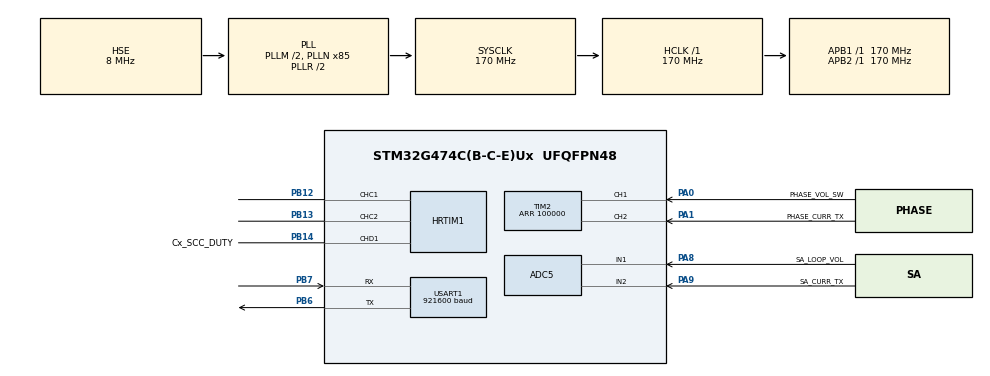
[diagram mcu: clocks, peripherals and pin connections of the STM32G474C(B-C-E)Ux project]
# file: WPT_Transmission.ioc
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ADC5.Channel-0\#ChannelRegularConversion=ADC_CHANNEL_1
ADC5.Channel-1\#ChannelRegularConversion=ADC_CHANNEL_2
ADC5.ClockPrescaler=ADC_CLOCK_SYNC_PCLK_DIV4
ADC5.ContinuousConvMode=ENABLE
ADC5.DMAContinuousRequests=ENABLE
ADC5.NbrOfConversion=2
ADC5.NbrOfConversionFlag=1
ADC5.OffsetNumber-0\#ChannelRegularConversion=ADC_OFFSET_NONE
ADC5.OffsetNumber-1\#ChannelRegularConversion=ADC_OFFSET_NONE
ADC5.Overrun=ADC_OVR_DATA_OVERWRITTEN
ADC5.Rank-0\#ChannelRegularConversion=1
ADC5.Rank-1\#ChannelRegularConversion=2
ADC5.SamplingTime-0\#ChannelRegularConversion=ADC_SAMPLETIME_47CYCLES_5
ADC5.SamplingTime-1\#ChannelRegularConversion=ADC_SAMPLETIME_47CYCLES_5
Dma.ADC5.0.Direction=DMA_PERIPH_TO_MEMORY
Dma.ADC5.0.EventEnable=DISABLE
Dma.ADC5.0.Instance=DMA1_Channel1
Dma.ADC5.0.MemDataAlignment=DMA_MDATAALIGN_HALFWORD
Dma.ADC5.0.MemInc=DMA_MINC_ENABLE
Dma.ADC5.0.Mode=DMA_CIRCULAR
Dma.ADC5.0.PeriphDataAlignment=DMA_PDATAALIGN_HALFWORD
Dma.ADC5.0.PeriphInc=DMA_PINC_DISABLE
Dma.ADC5.0.Polarity=HAL_DMAMUX_REQ_GEN_RISING
Dma.ADC5.0.Priority=DMA_PRIORITY_HIGH
Dma.ADC5.0.RequestNumber=1
Dma.ADC5.0.SignalID=NONE
Dma.ADC5.0.SyncEnable=DISABLE
Dma.ADC5.0.SyncPolarity=HAL_DMAMUX_SYNC_NO_EVENT
Dma.ADC5.0.SyncRequestNumber=1
Dma.ADC5.0.SyncSignalID=NONE
Dma.Request0=ADC5
Dma.Request1=USART1_TX
Dma.USART1_TX.1.Direction=DMA_MEMORY_TO_PERIPH
Dma.USART1_TX.1.EventEnable=DISABLE
Dma.USART1_TX.1.Instance=DMA1_Channel2
Dma.USART1_TX.1.MemDataAlignment=DMA_MDATAALIGN_BYTE
Dma.USART1_TX.1.MemInc=DMA_MINC_ENABLE
Dma.USART1_TX.1.Mode=DMA_NORMAL
Dma.USART1_TX.1.PeriphDataAlignment=DMA_PDATAALIGN_BYTE
Dma.USART1_TX.1.PeriphInc=DMA_PINC_DISABLE
Dma.USART1_TX.1.Polarity=HAL_DMAMUX_REQ_GEN_RISING
Dma.USART1_TX.1.Priority=DMA_PRIORITY_HIGH
Dma.USART1_TX.1.RequestNumber=1
Dma.USART1_TX.1.SignalID=NONE
Dma.USART1_TX.1.SyncEnable=DISABLE
Dma.USART1_TX.1.SyncPolarity=HAL_DMAMUX_SYNC_NO_EVENT
Dma.USART1_TX.1.SyncRequestNumber=1
Dma.USART1_TX.1.SyncSignalID=NONE
HRTIM1.CompareUnit1-Output_TC1TC2=HRTIM_COMPAREUNIT_1
HRTIM1.CompareUnit1-Output_TD1=HRTIM_COMPAREUNIT_1
HRTIM1.CompareValue1-Output_TC1TC2=((uint16_t)(HRCK_FREQ / DEFAULT_SWITCH_FREQ/2))
HRTIM1.CompareValue1-Output_TD1=((uint16_t)(HRCK_FREQ / DEFAULT_SWITCH_FREQ/10))
HRTIM1.DeadTimeInsertion-Output_TC1TC2=HRTIM_TIMDEADTIMEINSERTION_ENABLED
HRTIM1.Deadtimeconfig-Output_TC1TC2=HRTIM_TIMERINDEX_TIMER_C
HRTIM1.FallingValue-Output_TC1TC2=40
HRTIM1.NumberResetSource1-Output_TC1TC2=1
HRTIM1.NumberResetSource1-Output_TD1=1
HRTIM1.NumberResetSource2_TC=0
HRTIM1.NumberSetSource1-Output_TC1TC2=1
HRTIM1.NumberSetSource1-Output_TD1=1
HRTIM1.NumberSetSource2_TC=0
HRTIM1.Periode_TC=((uint16_t)(HRCK_FREQ / DEFAULT_SWITCH_FREQ))
HRTIM1.Periode_TD=((uint16_t)(HRCK_FREQ / DEFAULT_SWITCH_FREQ))
HRTIM1.PrescalerDead-Output_TC1TC2=HRTIM_TIMDEADTIME_PRESCALERRATIO_DIV1
HRTIM1.PrescalerRatio_TC=HRTIM_PRESCALERRATIO_MUL4
HRTIM1.PrescalerRatio_TD=HRTIM_PRESCALERRATIO_MUL4
HRTIM1.PushPull-Output_TC1TC2=HRTIM_TIMPUSHPULLMODE_DISABLED
HRTIM1.ResetOutput1_Source1-Output_TC1TC2=HRTIM_OUTPUTRESET_TIMCMP1
HRTIM1.ResetOutput1_Source1-Output_TD1=HRTIM_OUTPUTRESET_TIMCMP1
HRTIM1.RisingValue-Output_TC1TC2=40
HRTIM1.SetOutput1_Source1-Output_TC1TC2=HRTIM_OUTPUTSET_TIMPER
HRTIM1.SetOutput1_Source1-Output_TD1=HRTIM_OUTPUTSET_TIMPER
Mcu.Family=STM32G4
Mcu.Name=STM32G474C(B-C-E)Ux
Mcu.Package=UFQFPN48
NVIC.DMA1_Channel1_IRQn=true\:0\:0\:false\:false\:true\:false\:true
NVIC.DMA1_Channel2_IRQn=true\:0\:0\:false\:false\:true\:false\:true
NVIC.HRTIM1_TIMC_IRQn=true\:0\:0\:false\:false\:true\:true\:true
NVIC.PriorityGroup=NVIC_PRIORITYGROUP_4
NVIC.TIM1_UP_TIM16_IRQn=true\:0\:0\:false\:false\:true\:true\:true
NVIC.TIM2_IRQn=true\:0\:0\:false\:false\:true\:true\:true
NVIC.USART1_IRQn=true\:0\:0\:false\:false\:true\:true\:true
PA0.GPIO_Label=PHASE_VOL_SW
PA0.Signal=S_TIM2_CH1
PA1.GPIO_Label=PHASE_CURR_TX
PA1.Signal=S_TIM2_CH2
PA13.Mode=Serial_Wire
PA13.Signal=SYS_JTMS-SWDIO
PA14.Mode=Serial_Wire
PA14.Signal=SYS_JTCK-SWCLK
PA8.GPIO_Label=SA_LOOP_VOL
PA8.Mode=IN1-Single-Ended
PA8.Signal=ADC5_IN1
PA9.GPIO_Label=SA_CURR_TX
PA9.Mode=IN2-Single-Ended
PA9.Signal=ADC5_IN2
PB12.Mode=Output_TC1TC2
PB12.Signal=HRTIM1_CHC1
PB13.Mode=Output_TC1TC2
PB13.Signal=HRTIM1_CHC2
PB14.GPIO_Label=Cx_SCC_DUTY
PB14.Mode=Output_TD1
PB14.Signal=HRTIM1_CHD1
PB6.GPIO_Speed=GPIO_SPEED_FREQ_HIGH
PB6.Mode=Asynchronous
PB6.Signal=USART1_TX
PB7.GPIO_Speed=GPIO_SPEED_FREQ_HIGH
PB7.Mode=Asynchronous
PB7.Signal=USART1_RX
PF0-OSC_IN.Mode=HSE-External-Oscillator
PF0-OSC_IN.Signal=RCC_OSC_IN
PF1-OSC_OUT.Mode=HSE-External-Oscillator
PF1-OSC_OUT.Signal=RCC_OSC_OUT
ProjectManager.HeapSize=0x200
ProjectManager.StackSize=0x400
ProjectManager.TargetToolchain=MDK-ARM V5.27
RCC.ADC12Freq_Value=170000000
RCC.ADC345Freq_Value=170000000
RCC.AHBFreq_Value=170000000
RCC.APB1Freq_Value=170000000
RCC.APB1TimFreq_Value=170000000
RCC.APB2Freq_Value=170000000
RCC.APB2TimFreq_Value=170000000
RCC.CortexFreq_Value=170000000
RCC.EXTERNAL_CLOCK_VALUE=12288000
RCC.HCLKFreq_Value=170000000
RCC.HSE_VALUE=8000000
RCC.HSI48_VALUE=48000000
RCC.HSI_VALUE=16000000
RCC.LSE_VALUE=32768
RCC.PLLM=RCC_PLLM_DIV2
RCC.PLLN=85
RCC.PLLSourceVirtual=RCC_PLLSOURCE_HSE
RCC.SYSCLKFreq_VALUE=170000000
RCC.SYSCLKSource=RCC_SYSCLKSOURCE_PLLCLK
RCC.USBFreq_Value=170000000
RCC.VCOOutputFreq_Value=340000000
SH.S_TIM2_CH1.0=TIM2_CH1,Input_Capture1_from_TI1
SH.S_TIM2_CH1.1=TIM2_CH1,TriggerSource_TI1FP1
SH.S_TIM2_CH2.0=TIM2_CH2,Input_Capture2_from_TI2
TIM1.PeriodNoDither=((uint16_t)(TIMCK_FREQ/SAMPLING_FREQ) - 1)
TIM2.Channel-Input_Capture1_from_TI1=TIM_CHANNEL_1
TIM2.Channel-Input_Capture2_from_TI2=TIM_CHANNEL_2
TIM2.ICFilter_CH1=5
TIM2.ICFilter_CH2=5
TIM2.ICPolarity_CH1=TIM_INPUTCHANNELPOLARITY_RISING
TIM2.ICPolarity_CH2=TIM_INPUTCHANNELPOLARITY_RISING
TIM2.PeriodNoDither=100000
USART1.BaudRate=921600
USART1.VirtualMode-Asynchronous=VM_ASYNC
VP_SYS_VS_DBSignals.Mode=DisableDeadBatterySignals
VP_TIM1_VS_ClockSourceINT.Mode=Internal
VP_TIM2_VS_ClockSourceINT.Mode=Internal
VP_TIM2_VS_ControllerModeReset.Mode=Reset Mode
board=custom

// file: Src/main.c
/* USER CODE BEGIN Header */
/**
  ******************************************************************************
  * @file           : main.c
  * @brief          : Main program body
  ******************************************************************************
  * @attention
  *
  * <h2><center>&copy; Copyright (c) 2020 STMicroelectronics.
  * All rights reserved.</center></h2>
  *
  * This software component is licensed by ST under BSD 3-Clause license,
  * the "License"; You may not use this file except in compliance with the
  * License. You may obtain a copy of the License at:
  *                        opensource.org/licenses/BSD-3-Clause
  *
  ******************************************************************************
  */
/* USER CODE END Header */
#include "main.h"
#include "adc.h"
#include "dma.h"
#include "hrtim.h"
#include "hrtim.h"
#include "tim.h"
#include "usart.h"
#include "gpio.h"

/* USER CODE BEGIN PV */
extern struct WptTx_t WptTx;
/* USER CODE END PV */

void SystemClock_Config(void);

int main(void)
{

  /* MCU Configuration--------------------------------------------------------*/

  /* Reset of all peripherals, Initializes the Flash interface and the Systick. */
  HAL_Init();

  /* Configure the system clock */
  SystemClock_Config();

  /* Initialize all configured peripherals */
  MX_GPIO_Init();
  MX_DMA_Init();
  MX_ADC5_Init();
  MX_HRTIM1_Init();
  MX_USART1_UART_Init();
  MX_TIM1_Init();
  MX_TIM2_Init();
  /* USER CODE BEGIN 2 */
  HAL_Delay(500);
  UART_Enable();
  WPT_Tx_Init();
  TIM_Enable();
  /* USER CODE END 2 */

  /* Infinite loop */
  while (1)
  {

  }
}

void SystemClock_Config(void)
{
  RCC_OscInitTypeDef RCC_OscInitStruct = {0};
  RCC_ClkInitTypeDef RCC_ClkInitStruct = {0};
  RCC_PeriphCLKInitTypeDef PeriphClkInit = {0};

  /** Configure the main internal regulator output voltage
  */
  HAL_PWREx_ControlVoltageScaling(PWR_REGULATOR_VOLTAGE_SCALE1_BOOST);
  /** Initializes the RCC Oscillators according to the specified parameters
  * in the RCC_OscInitTypeDef structure.
  */
  RCC_OscInitStruct.OscillatorType = RCC_OSCILLATORTYPE_HSE;
  RCC_OscInitStruct.HSEState = RCC_HSE_ON;
  RCC_OscInitStruct.PLL.PLLState = RCC_PLL_ON;
  RCC_OscInitStruct.PLL.PLLSource = RCC_PLLSOURCE_HSE;
  RCC_OscInitStruct.PLL.PLLM = RCC_PLLM_DIV2;
  RCC_OscInitStruct.PLL.PLLN = 85;
  RCC_OscInitStruct.PLL.PLLP = RCC_PLLP_DIV2;
  RCC_OscInitStruct.PLL.PLLQ = RCC_PLLQ_DIV2;
  RCC_OscInitStruct.PLL.PLLR = RCC_PLLR_DIV2;
  if (HAL_RCC_OscConfig(&RCC_OscInitStruct) != HAL_OK)
  {
    Error_Handler();
  }
  /** Initializes the CPU, AHB and APB buses clocks
  */
  RCC_ClkInitStruct.ClockType = RCC_CLOCKTYPE_HCLK|RCC_CLOCKTYPE_SYSCLK
                              |RCC_CLOCKTYPE_PCLK1|RCC_CLOCKTYPE_PCLK2;
  RCC_ClkInitStruct.SYSCLKSource = RCC_SYSCLKSOURCE_PLLCLK;
  RCC_ClkInitStruct.AHBCLKDivider = RCC_SYSCLK_DIV1;
  RCC_ClkInitStruct.APB1CLKDivider = RCC_HCLK_DIV1;
  RCC_ClkInitStruct.APB2CLKDivider = RCC_HCLK_DIV1;

  if (HAL_RCC_ClockConfig(&RCC_ClkInitStruct, FLASH_LATENCY_4) != HAL_OK)
  {
    Error_Handler();
  }
  /** Initializes the peripherals clocks
  */
  PeriphClkInit.PeriphClockSelection = RCC_PERIPHCLK_USART1|RCC_PERIPHCLK_ADC345;
  PeriphClkInit.Usart1ClockSelection = RCC_USART1CLKSOURCE_PCLK2;
  PeriphClkInit.Adc345ClockSelection = RCC_ADC345CLKSOURCE_SYSCLK;
  if (HAL_RCCEx_PeriphCLKConfig(&PeriphClkInit) != HAL_OK)
  {
    Error_Handler();
  }
}

void Error_Handler(void)
{
}

/************************ (C) COPYRIGHT STMicroelectronics *****END OF FILE****/
